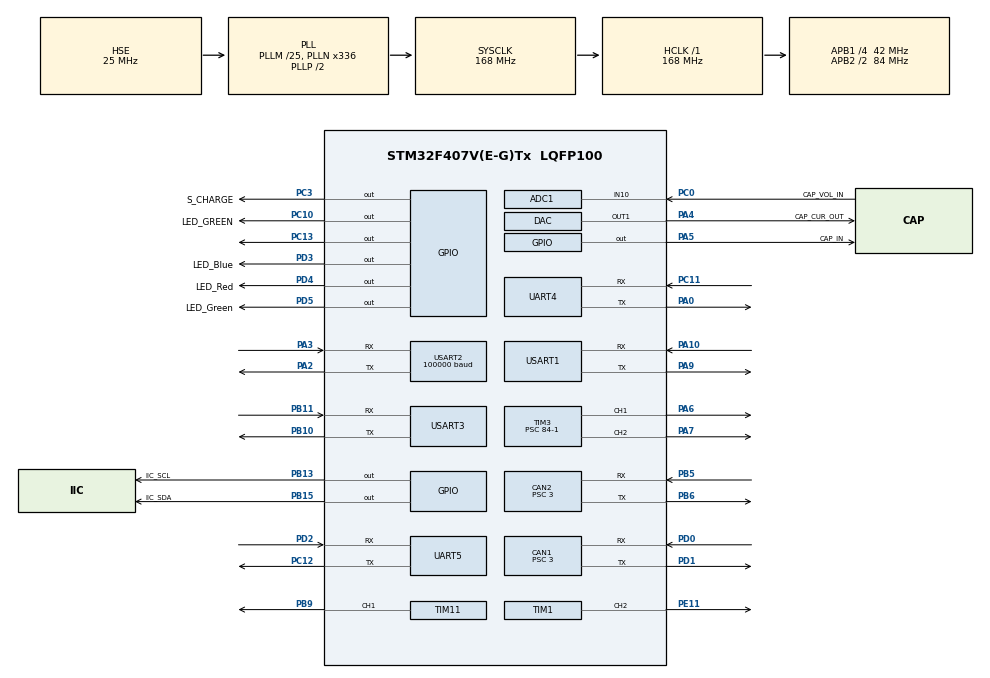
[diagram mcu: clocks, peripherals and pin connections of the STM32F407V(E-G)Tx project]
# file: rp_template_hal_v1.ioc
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ADC1.Channel-0\#ChannelRegularConversion=ADC_CHANNEL_10
ADC1.NbrOfConversionFlag=1
ADC1.Rank-0\#ChannelRegularConversion=1
ADC1.SamplingTime-0\#ChannelRegularConversion=ADC_SAMPLETIME_3CYCLES
ADC1.master=1
CAN1.BS1=CAN_BS1_9TQ
CAN1.BS2=CAN_BS2_4TQ
CAN1.CalculateTimeQuantum=71.42857142857143
CAN1.Prescaler=3
CAN1.TXFP=ENABLE
CAN2.BS1=CAN_BS1_9TQ
CAN2.BS2=CAN_BS2_4TQ
CAN2.CalculateTimeQuantum=71.42857142857143
CAN2.Prescaler=3
CAN2.TXFP=ENABLE
DAC.DAC_OutputBuffer=DAC_OUTPUTBUFFER_DISABLE
Dma.Request0=UART5_RX
Dma.Request1=USART1_RX
Dma.Request2=UART4_RX
Dma.Request3=UART5_TX
Dma.UART4_RX.2.Direction=DMA_PERIPH_TO_MEMORY
Dma.UART4_RX.2.FIFOMode=DMA_FIFOMODE_DISABLE
Dma.UART4_RX.2.Instance=DMA1_Stream2
Dma.UART4_RX.2.MemDataAlignment=DMA_MDATAALIGN_BYTE
Dma.UART4_RX.2.MemInc=DMA_MINC_ENABLE
Dma.UART4_RX.2.Mode=DMA_CIRCULAR
Dma.UART4_RX.2.PeriphDataAlignment=DMA_PDATAALIGN_BYTE
Dma.UART4_RX.2.PeriphInc=DMA_PINC_DISABLE
Dma.UART4_RX.2.Priority=DMA_PRIORITY_LOW
Dma.UART5_RX.0.Direction=DMA_PERIPH_TO_MEMORY
Dma.UART5_RX.0.FIFOMode=DMA_FIFOMODE_DISABLE
Dma.UART5_RX.0.Instance=DMA1_Stream0
Dma.UART5_RX.0.MemDataAlignment=DMA_MDATAALIGN_BYTE
Dma.UART5_RX.0.MemInc=DMA_MINC_ENABLE
Dma.UART5_RX.0.Mode=DMA_CIRCULAR
Dma.UART5_RX.0.PeriphDataAlignment=DMA_PDATAALIGN_BYTE
Dma.UART5_RX.0.PeriphInc=DMA_PINC_DISABLE
Dma.UART5_RX.0.Priority=DMA_PRIORITY_VERY_HIGH
Dma.UART5_TX.3.Direction=DMA_MEMORY_TO_PERIPH
Dma.UART5_TX.3.FIFOMode=DMA_FIFOMODE_DISABLE
Dma.UART5_TX.3.Instance=DMA1_Stream7
Dma.UART5_TX.3.MemDataAlignment=DMA_MDATAALIGN_BYTE
Dma.UART5_TX.3.MemInc=DMA_MINC_ENABLE
Dma.UART5_TX.3.Mode=DMA_CIRCULAR
Dma.UART5_TX.3.PeriphDataAlignment=DMA_PDATAALIGN_BYTE
Dma.UART5_TX.3.PeriphInc=DMA_PINC_DISABLE
Dma.UART5_TX.3.Priority=DMA_PRIORITY_VERY_HIGH
Dma.USART1_RX.1.Direction=DMA_PERIPH_TO_MEMORY
Dma.USART1_RX.1.FIFOMode=DMA_FIFOMODE_DISABLE
Dma.USART1_RX.1.Instance=DMA2_Stream2
Dma.USART1_RX.1.MemDataAlignment=DMA_MDATAALIGN_BYTE
Dma.USART1_RX.1.MemInc=DMA_MINC_ENABLE
Dma.USART1_RX.1.Mode=DMA_CIRCULAR
Dma.USART1_RX.1.PeriphDataAlignment=DMA_PDATAALIGN_BYTE
Dma.USART1_RX.1.PeriphInc=DMA_PINC_DISABLE
Dma.USART1_RX.1.Priority=DMA_PRIORITY_HIGH
FREERTOS.Tasks01=MonitorTask,0,256,StartMonitorTask,As weak,NULL,Dynamic,NULL,NULL;Check_Task,-3,128,CheckTask,As external,NULL,Dynamic,NULL,NULL;BMI_Task,-3,128,BmiUpdateTask,As external,NULL,Dynamic,NULL,NULL
Mcu.Family=STM32F4
Mcu.Name=STM32F407V(E-G)Tx
Mcu.Package=LQFP100
NVIC.CAN1_RX0_IRQn=true\:0\:0\:false\:false\:true\:true\:true\:true\:true
NVIC.CAN2_RX0_IRQn=true\:0\:0\:false\:false\:true\:true\:true\:true\:true
NVIC.DMA1_Stream0_IRQn=true\:0\:0\:false\:false\:true\:true\:false\:true\:true
NVIC.DMA1_Stream2_IRQn=true\:0\:0\:false\:false\:true\:true\:false\:true\:true
NVIC.DMA1_Stream7_IRQn=true\:0\:0\:false\:false\:true\:true\:false\:true\:true
NVIC.DMA2_Stream2_IRQn=true\:0\:0\:false\:false\:true\:true\:false\:true\:true
NVIC.PriorityGroup=NVIC_PRIORITYGROUP_4
NVIC.TIM2_IRQn=true\:0\:0\:false\:false\:true\:false\:false\:true\:true
NVIC.TimeBase=TIM2_IRQn
NVIC.TimeBaseIP=TIM2
NVIC.UART4_IRQn=true\:0\:0\:false\:false\:true\:true\:true\:true\:true
NVIC.UART5_IRQn=true\:0\:0\:false\:false\:true\:true\:true\:true\:true
NVIC.USART1_IRQn=true\:0\:0\:false\:false\:true\:true\:true\:true\:true
PA0-WKUP.Mode=Asynchronous
PA0-WKUP.Signal=UART4_TX
PA10.Mode=Asynchronous
PA10.Signal=USART1_RX
PA2.Mode=Asynchronous
PA2.Signal=USART2_TX
PA3.Mode=Asynchronous
PA3.Signal=USART2_RX
PA4.GPIO_Label=CAP_CUR_OUT
PA4.Signal=COMP_DAC1_group
PA5.GPIO_Label=CAP_IN
PA5.GPIO_Speed=GPIO_SPEED_FREQ_VERY_HIGH
PA5.Signal=GPIO_Output
PA6.Signal=S_TIM3_CH1
PA7.Signal=S_TIM3_CH2
PA9.Mode=Asynchronous
PA9.Signal=USART1_TX
PB10.Mode=Asynchronous
PB10.Signal=USART3_TX
PB11.Mode=Asynchronous
PB11.Signal=USART3_RX
PB13.GPIO_Label=IIC_SCL
PB13.GPIO_Speed=GPIO_SPEED_FREQ_VERY_HIGH
PB13.PinState=GPIO_PIN_SET
PB13.Signal=GPIO_Output
PB15.GPIO_Label=IIC_SDA
PB15.GPIO_Speed=GPIO_SPEED_FREQ_VERY_HIGH
PB15.PinState=GPIO_PIN_SET
PB15.Signal=GPIO_Output
PB5.Mode=Slave
PB5.Signal=CAN2_RX
PB6.Mode=Slave
PB6.Signal=CAN2_TX
PB9.Signal=S_TIM11_CH1
PC0.GPIO_Label=CAP_VOL_IN
PC0.Signal=ADCx_IN10
PC10.GPIO_Label=LED_GREEN
PC10.GPIO_Speed=GPIO_SPEED_FREQ_LOW
PC10.PinState=GPIO_PIN_SET
PC10.Signal=GPIO_Output
PC11.Mode=Asynchronous
PC11.Signal=UART4_RX
PC12.Mode=Asynchronous
PC12.Signal=UART5_TX
PC13-ANTI_TAMP.Signal=GPIO_Output
PC3.GPIO_Label=S_CHARGE
PC3.GPIO_Speed=GPIO_SPEED_FREQ_VERY_HIGH
PC3.Signal=GPIO_Output
PD0.Mode=Master
PD0.Signal=CAN1_RX
PD1.Mode=Master
PD1.Signal=CAN1_TX
PD2.Mode=Asynchronous
PD2.Signal=UART5_RX
PD3.GPIO_Label=LED_Blue
PD3.PinState=GPIO_PIN_SET
PD3.Signal=GPIO_Output
PD4.GPIO_Label=LED_Red
PD4.PinState=GPIO_PIN_SET
PD4.Signal=GPIO_Output
PD5.GPIO_Label=LED_Green
PD5.PinState=GPIO_PIN_SET
PD5.Signal=GPIO_Output
PE11.Signal=S_TIM1_CH2
PH0-OSC_IN.Mode=HSE-External-Oscillator
PH0-OSC_IN.Signal=RCC_OSC_IN
PH1-OSC_OUT.Mode=HSE-External-Oscillator
PH1-OSC_OUT.Signal=RCC_OSC_OUT
ProjectManager.HeapSize=0x200
ProjectManager.StackSize=0x400
ProjectManager.TargetToolchain=MDK-ARM V5
RCC.48MHZClocksFreq_Value=84000000
RCC.AHBFreq_Value=168000000
RCC.APB1CLKDivider=RCC_HCLK_DIV4
RCC.APB1Freq_Value=42000000
RCC.APB1TimFreq_Value=84000000
RCC.APB2CLKDivider=RCC_HCLK_DIV2
RCC.APB2Freq_Value=84000000
RCC.APB2TimFreq_Value=168000000
RCC.CortexFreq_Value=168000000
RCC.HCLKFreq_Value=168000000
RCC.HSE_VALUE=25000000
RCC.HSI_VALUE=16000000
RCC.LSE_VALUE=32768
RCC.PLLM=25
RCC.PLLN=336
RCC.PLLSourceVirtual=RCC_PLLSOURCE_HSE
RCC.SYSCLKFreq_VALUE=168000000
RCC.SYSCLKSource=RCC_SYSCLKSOURCE_PLLCLK
RCC.VCOOutputFreq_Value=336000000
SH.ADCx_IN10.0=ADC1_IN10,IN10
SH.COMP_DAC1_group.0=DAC_OUT1,DAC_OUT1
SH.S_TIM11_CH1.0=TIM11_CH1,PWM Generation1 CH1
SH.S_TIM1_CH2.0=TIM1_CH2,PWM Generation2 CH2
SH.S_TIM3_CH1.0=TIM3_CH1,PWM Generation1 CH1
SH.S_TIM3_CH2.0=TIM3_CH2,PWM Generation2 CH2
TIM1.Channel-PWM\ Generation2\ CH2=TIM_CHANNEL_2
TIM1.Period=1000-1
TIM1.Prescaler=3360-1
TIM11.Channel=TIM_CHANNEL_1
TIM11.Period=1000
TIM11.Prescaler=168 -1 
TIM3.Channel-PWM\ Generation1\ CH1=TIM_CHANNEL_1
TIM3.Channel-PWM\ Generation2\ CH2=TIM_CHANNEL_2
TIM3.Period=2500-1
TIM3.Prescaler=84-1
UART4.VirtualMode=Asynchronous
UART5.VirtualMode=Asynchronous
USART1.VirtualMode=VM_ASYNC
USART2.BaudRate=100000
USART2.VirtualMode=VM_ASYNC
USART3.VirtualMode=VM_ASYNC
VP_FREERTOS_VS_CMSIS_V1.Mode=CMSIS_V1
VP_SYS_VS_tim2.Mode=TIM2
VP_TIM11_VS_ClockSourceINT.Mode=Enable_Timer
VP_TIM1_VS_ClockSourceINT.Mode=Internal
VP_TIM3_VS_ClockSourceINT.Mode=Internal
board=custom

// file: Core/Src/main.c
/* USER CODE BEGIN Header */
/**
  ******************************************************************************
  * @file           : main.c
  * @brief          : Main program body
  ******************************************************************************
  * @attention
  *
  * <h2><center>&copy; Copyright (c) 2023 STMicroelectronics.
  * All rights reserved.</center></h2>
  *
  * This software component is licensed by ST under Ultimate Liberty license
  * SLA0044, the "License"; You may not use this file except in compliance with
  * the License. You may obtain a copy of the License at:
  *                             www.st.com/SLA0044
  *
  ******************************************************************************
  */
/* USER CODE END Header */
#include "main.h"
#include "cmsis_os.h"
#include "adc.h"
#include "can.h"
#include "dac.h"
#include "dma.h"
#include "tim.h"
#include "usart.h"
#include "gpio.h"

/* USER CODE BEGIN Includes */
#include "driver.h"
#include "bmi.h"

/* USER CODE END Includes */

/* USER CODE BEGIN PTD */
bmi_t bmi_structure;
short gyrox, gyroy, gyroz;
short accx, accy, accz;
/* USER CODE END PTD */

/* USER CODE BEGIN PV */
int i = 0;

/* USER CODE END PV */

void SystemClock_Config(void);
void MX_FREERTOS_Init(void);

int main(void)
{

  /* MCU Configuration--------------------------------------------------------*/

  /* Reset of all peripherals, Initializes the Flash interface and the Systick. */
  HAL_Init();

  /* Configure the system clock */
  SystemClock_Config();

  /* Initialize all configured peripherals */
  MX_GPIO_Init();
  MX_DMA_Init();
  MX_TIM3_Init();
  MX_USART2_UART_Init();
  MX_CAN1_Init();
  MX_CAN2_Init();
  MX_TIM1_Init();
  MX_ADC1_Init();
  MX_DAC_Init();
  MX_UART4_Init();
  MX_UART5_Init();
  MX_USART1_UART_Init();
  MX_USART3_UART_Init();
  MX_TIM11_Init();
  /* USER CODE BEGIN 2 */

  DRIVER_Init();
  /*初始化*/
  /* USER CODE END 2 */
	while(1)
	{
		 HAL_GPIO_WritePin(GPIOD, LED_Blue_Pin|LED_Red_Pin|LED_Green_Pin, GPIO_PIN_RESET);
		 BUZZ_Freq(100);

	}
  /* Call init function for freertos objects (in freertos.c) */
  MX_FREERTOS_Init();
  /* Start scheduler */
  osKernelStart();

  /* We should never get here as control is now taken by the scheduler */
  /* Infinite loop */
  while (1)
  {

  }
}

void SystemClock_Config(void)
{
  RCC_OscInitTypeDef RCC_OscInitStruct = {0};
  RCC_ClkInitTypeDef RCC_ClkInitStruct = {0};

  /** Configure the main internal regulator output voltage
  */
  __HAL_RCC_PWR_CLK_ENABLE();
  __HAL_PWR_VOLTAGESCALING_CONFIG(PWR_REGULATOR_VOLTAGE_SCALE1);
  /** Initializes the RCC Oscillators according to the specified parameters
  * in the RCC_OscInitTypeDef structure.
  */
  RCC_OscInitStruct.OscillatorType = RCC_OSCILLATORTYPE_HSE;
  RCC_OscInitStruct.HSEState = RCC_HSE_ON;
  RCC_OscInitStruct.PLL.PLLState = RCC_PLL_ON;
  RCC_OscInitStruct.PLL.PLLSource = RCC_PLLSOURCE_HSE;
  RCC_OscInitStruct.PLL.PLLM = 25;
  RCC_OscInitStruct.PLL.PLLN = 336;
  RCC_OscInitStruct.PLL.PLLP = RCC_PLLP_DIV2;
  RCC_OscInitStruct.PLL.PLLQ = 4;
  if (HAL_RCC_OscConfig(&RCC_OscInitStruct) != HAL_OK)
  {
    Error_Handler();
  }
  /** Initializes the CPU, AHB and APB buses clocks
  */
  RCC_ClkInitStruct.ClockType = RCC_CLOCKTYPE_HCLK|RCC_CLOCKTYPE_SYSCLK
                              |RCC_CLOCKTYPE_PCLK1|RCC_CLOCKTYPE_PCLK2;
  RCC_ClkInitStruct.SYSCLKSource = RCC_SYSCLKSOURCE_PLLCLK;
  RCC_ClkInitStruct.AHBCLKDivider = RCC_SYSCLK_DIV1;
  RCC_ClkInitStruct.APB1CLKDivider = RCC_HCLK_DIV4;
  RCC_ClkInitStruct.APB2CLKDivider = RCC_HCLK_DIV2;

  if (HAL_RCC_ClockConfig(&RCC_ClkInitStruct, FLASH_LATENCY_5) != HAL_OK)
  {
    Error_Handler();
  }
}

void HAL_TIM_PeriodElapsedCallback(TIM_HandleTypeDef *htim)
{
  if (htim->Instance == TIM2) {
    HAL_IncTick();
  }
}

void Error_Handler(void)
{
}

/************************ (C) COPYRIGHT STMicroelectronics *****END OF FILE****/

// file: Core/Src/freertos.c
/* USER CODE BEGIN Header */
/**
  ******************************************************************************
  * File Name          : freertos.c
  * Description        : Code for freertos applications
  ******************************************************************************
  * @attention
  *
  * <h2><center>&copy; Copyright (c) 2023 STMicroelectronics.
  * All rights reserved.</center></h2>
  *
  * This software component is licensed by ST under Ultimate Liberty license
  * SLA0044, the "License"; You may not use this file except in compliance with
  * the License. You may obtain a copy of the License at:
  *                             www.st.com/SLA0044
  *
  ******************************************************************************
  */
/* USER CODE END Header */

#include "FreeRTOS.h"
#include "task.h"
#include "main.h"
#include "cmsis_os.h"

osThreadId MonitorTaskHandle;
osThreadId Check_TaskHandle;
osThreadId BMI_TaskHandle;

void StartMonitorTask(void const * argument);
extern void CheckTask(void const * argument);
extern void BmiUpdateTask(void const * argument);

void MX_FREERTOS_Init(void); /* (MISRA C 2004 rule 8.1) */

/* GetIdleTaskMemory prototype (linked to static allocation support) */
void vApplicationGetIdleTaskMemory( StaticTask_t **ppxIdleTaskTCBBuffer, StackType_t **ppxIdleTaskStackBuffer, uint32_t *pulIdleTaskStackSize );

/* USER CODE BEGIN GET_IDLE_TASK_MEMORY */
static StaticTask_t xIdleTaskTCBBuffer;
static StackType_t xIdleStack[configMINIMAL_STACK_SIZE];

void vApplicationGetIdleTaskMemory( StaticTask_t **ppxIdleTaskTCBBuffer, StackType_t **ppxIdleTaskStackBuffer, uint32_t *pulIdleTaskStackSize )
{
  *ppxIdleTaskTCBBuffer = &xIdleTaskTCBBuffer;
  *ppxIdleTaskStackBuffer = &xIdleStack[0];
  *pulIdleTaskStackSize = configMINIMAL_STACK_SIZE;
  /* place for user code */
}
/* USER CODE END GET_IDLE_TASK_MEMORY */

void MX_FREERTOS_Init(void) {

  /* Create the thread(s) */
  /* definition and creation of MonitorTask */
  osThreadDef(MonitorTask, StartMonitorTask, osPriorityNormal, 0, 256);
  MonitorTaskHandle = osThreadCreate(osThread(MonitorTask), NULL);

  /* definition and creation of Check_Task */
  osThreadDef(Check_Task, CheckTask, osPriorityIdle, 0, 128);
  Check_TaskHandle = osThreadCreate(osThread(Check_Task), NULL);

  /* definition and creation of BMI_Task */
  osThreadDef(BMI_Task, BmiUpdateTask, osPriorityIdle, 0, 128);
  BMI_TaskHandle = osThreadCreate(osThread(BMI_Task), NULL);

}

__weak void StartMonitorTask(void const * argument)
{
  for(;;)
  {
    osDelay(1);
  }
}

/************************ (C) COPYRIGHT STMicroelectronics *****END OF FILE****/
